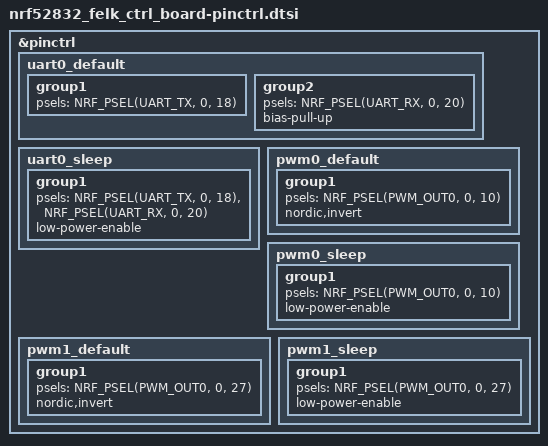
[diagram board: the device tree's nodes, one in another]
&pinctrl {

	uart0_default: uart0_default {
		group1 {
			psels = <NRF_PSEL(UART_TX, 0, 18)>;
		};
		group2 {
			psels = <NRF_PSEL(UART_RX, 0, 20)>;
			bias-pull-up;
		};
	};

	uart0_sleep: uart0_sleep {
		group1 {
			psels = <NRF_PSEL(UART_TX, 0, 18)>,
				<NRF_PSEL(UART_RX, 0, 20)>;
			low-power-enable;
		};
    };

	pwm0_default: pwm0_default {
		group1 {
			psels = <NRF_PSEL(PWM_OUT0, 0, 10)>;
			nordic,invert;
		};
	};

	pwm0_sleep: pwm0_sleep {
		group1 {
			psels = <NRF_PSEL(PWM_OUT0, 0, 10)>;
			low-power-enable;
		};
	};

    pwm1_default: pwm1_default {
		group1 {
			psels = <NRF_PSEL(PWM_OUT0, 0, 27)>;
			nordic,invert;
		};
	};

	pwm1_sleep: pwm1_sleep {
		group1 {
			psels = <NRF_PSEL(PWM_OUT0, 0, 27)>;
			low-power-enable;
		};
	};


};
